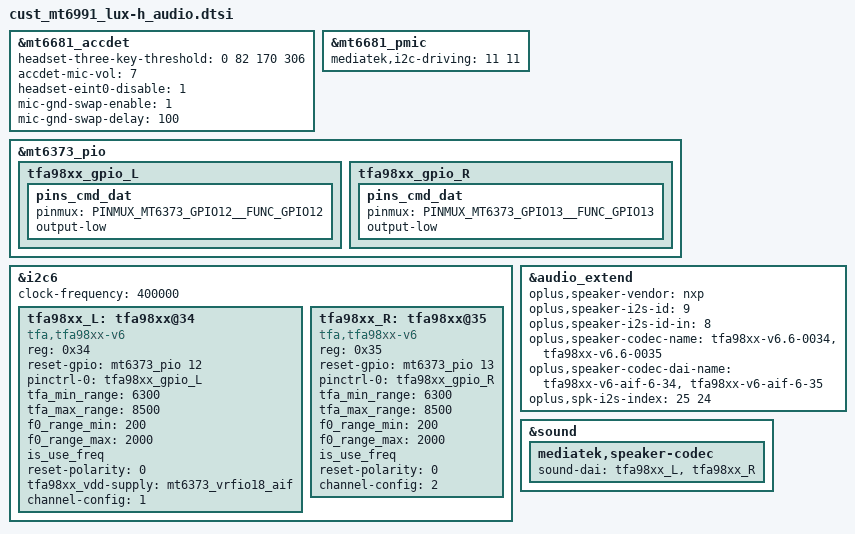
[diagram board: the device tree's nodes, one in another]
// SPDX-License-Identifier: GPL-2.0
/* Copyright (c) 2020 MediaTek Inc. */
#include <dt-bindings/pinctrl/mt6373-pinfunc.h>

&mt6681_accdet {
	headset-three-key-threshold = <0 82 170 306>;
	accdet-mic-vol = <7>;
	// add for supporting type-c headphone detect bypass
	headset-eint0-disable = <1>;
	mic-gnd-swap-enable = <1>;
	mic-gnd-swap-delay = <100>;
};

&mt6681_pmic {
	mediatek,i2c-driving = <11 11>;
};

&mt6373_pio {
 	tfa98xx_gpio_L: tfa98xx_gpio_L {
 		pins_cmd_dat {
			pinmux = <PINMUX_MT6373_GPIO12__FUNC_GPIO12>;
			output-low;
		};
 	};

 	tfa98xx_gpio_R: tfa98xx_gpio_R {
 		pins_cmd_dat {
			pinmux = <PINMUX_MT6373_GPIO13__FUNC_GPIO13>;
 			output-low;
		};
	};
};

&i2c6 {
	clock-frequency = <400000>;

	tfa98xx_L: tfa98xx@34{
		compatible = "tfa,tfa98xx-v6";
		reg = <0x34>;
		reset-gpio = <&mt6373_pio 12 0>;
		pinctrl-names = "default";
		pinctrl-0 = <&tfa98xx_gpio_L>;
		tfa_min_range = <6300>;
		tfa_max_range = <8500>;
		f0_range_min = <200>;
		f0_range_max = <2000>;
		is_use_freq;
		reset-polarity = <0>;
		tfa98xx_vdd-supply = <&mt6373_vrfio18_aif>;
		channel-config = <1>;
		status = "okay";
	};

	tfa98xx_R: tfa98xx@35{
		compatible = "tfa,tfa98xx-v6";
		reg = <0x35>;
		reset-gpio = <&mt6373_pio 13 0>;
		pinctrl-names = "default";
		pinctrl-0 = <&tfa98xx_gpio_R>;
		tfa_min_range = <6300>;
		tfa_max_range = <8500>;
		f0_range_min = <200>;
		f0_range_max = <2000>;
		is_use_freq;
		reset-polarity = <0>;
		channel-config = <2>;
		status = "okay";
	};

};

&audio_extend {
 	//for nxp speaker
 	oplus,speaker-vendor = "nxp";
 	oplus,speaker-i2s-id = <9>;
 	oplus,speaker-i2s-id-in = <8>;
	oplus,speaker-codec-name = "tfa98xx-v6.6-0034","tfa98xx-v6.6-0035";
	oplus,speaker-codec-dai-name = "tfa98xx-v6-aif-6-34","tfa98xx-v6-aif-6-35";
	oplus,spk-i2s-index = <25 24>;
};

&sound {
//	mtk_spk_i2s_out = <3>;
//	mtk_spk_i2s_in = <9>;
	mediatek,speaker-codec {
		sound-dai = <&tfa98xx_L>, <&tfa98xx_R>;
	};

};
